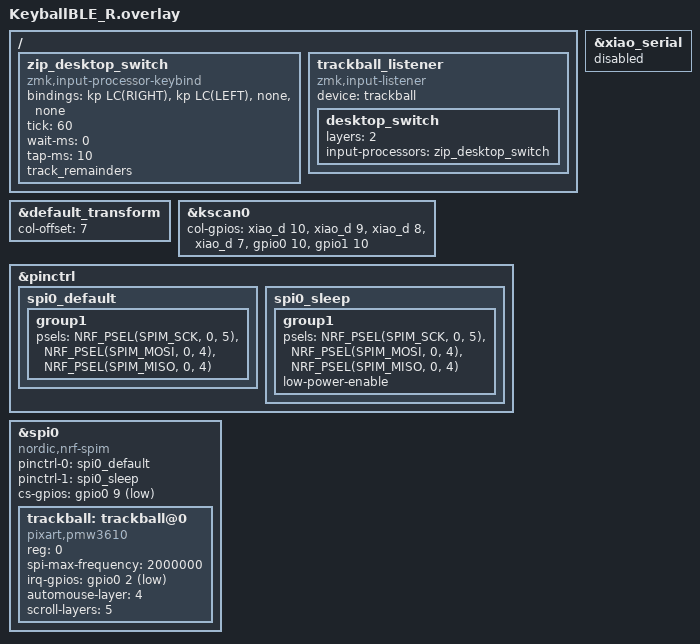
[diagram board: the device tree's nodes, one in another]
#include "KeyballBLE.dtsi"
#include <dt-bindings/zmk/keys.h>
#include <dt-bindings/zmk/input-processor-keybind.h>

&default_transform {
    col-offset = <7>;
};

&kscan0 {
        col-gpios
            = <&xiao_d 10 GPIO_ACTIVE_HIGH>
            , <&xiao_d 9 GPIO_ACTIVE_HIGH> 
            , <&xiao_d 8 GPIO_ACTIVE_HIGH> 
            , <&xiao_d 7 GPIO_ACTIVE_HIGH> 
            , <&gpio0 10 GPIO_ACTIVE_HIGH>
            , <&gpio1 10 GPIO_ACTIVE_HIGH>
            ;
};

/ {
    // レイヤー2でトラックボールを左右に動かすと Ctrl+←/→ (macOSのデスクトップ切替) を送る。
    // 上下の動きは無効。動きは消費するのでカーソルは動かない。
    zip_desktop_switch: zip_desktop_switch {
        compatible = "zmk,input-processor-keybind";
        #input-processor-cells = <0>;
        bindings = <&kp LC(RIGHT)>,   // 右へ → 次のデスクトップ
                   <&kp LC(LEFT)>,    // 左へ → 前のデスクトップ
                   <&none>,           // 上 → 無効
                   <&none>;           // 下 → 無効
        tick = <60>;       // 1切替に必要な移動量(大きいほど鈍感)
        wait-ms = <0>;
        tap-ms = <10>;
        track_remainders;
    };

    trackball_listener {
        compatible = "zmk,input-listener";
        device = <&trackball>;

        desktop_switch {
            layers = <2>;
            input-processors = <&zip_desktop_switch>;
        };
    };
};

&pinctrl {
    spi0_default: spi0_default {
        group1 {
            psels = <NRF_PSEL(SPIM_SCK, 0, 5)>,
                <NRF_PSEL(SPIM_MOSI, 0, 4)>,
                <NRF_PSEL(SPIM_MISO, 0, 4)>;
        };
    };

    spi0_sleep: spi0_sleep {
        group1 {
            psels = <NRF_PSEL(SPIM_SCK, 0, 5)>,
                <NRF_PSEL(SPIM_MOSI, 0, 4)>,
                <NRF_PSEL(SPIM_MISO, 0, 4)>;
            low-power-enable;
        };
    };
};

&xiao_serial { status = "disabled"; };

&spi0 {
    status = "okay";
    compatible = "nordic,nrf-spim";
    pinctrl-0 = <&spi0_default>;
    pinctrl-1 = <&spi0_sleep>;
    pinctrl-names = "default", "sleep";
    cs-gpios = <&gpio0 9 GPIO_ACTIVE_LOW>;

    trackball: trackball@0 {
        status = "okay";
        compatible = "pixart,pmw3610";
        reg = <0>;
        spi-max-frequency = <2000000>;
        irq-gpios = <&gpio0 2 (GPIO_ACTIVE_LOW | GPIO_PULL_UP)>;
        automouse-layer = <4>;
        scroll-layers = <5>;
    };
};


